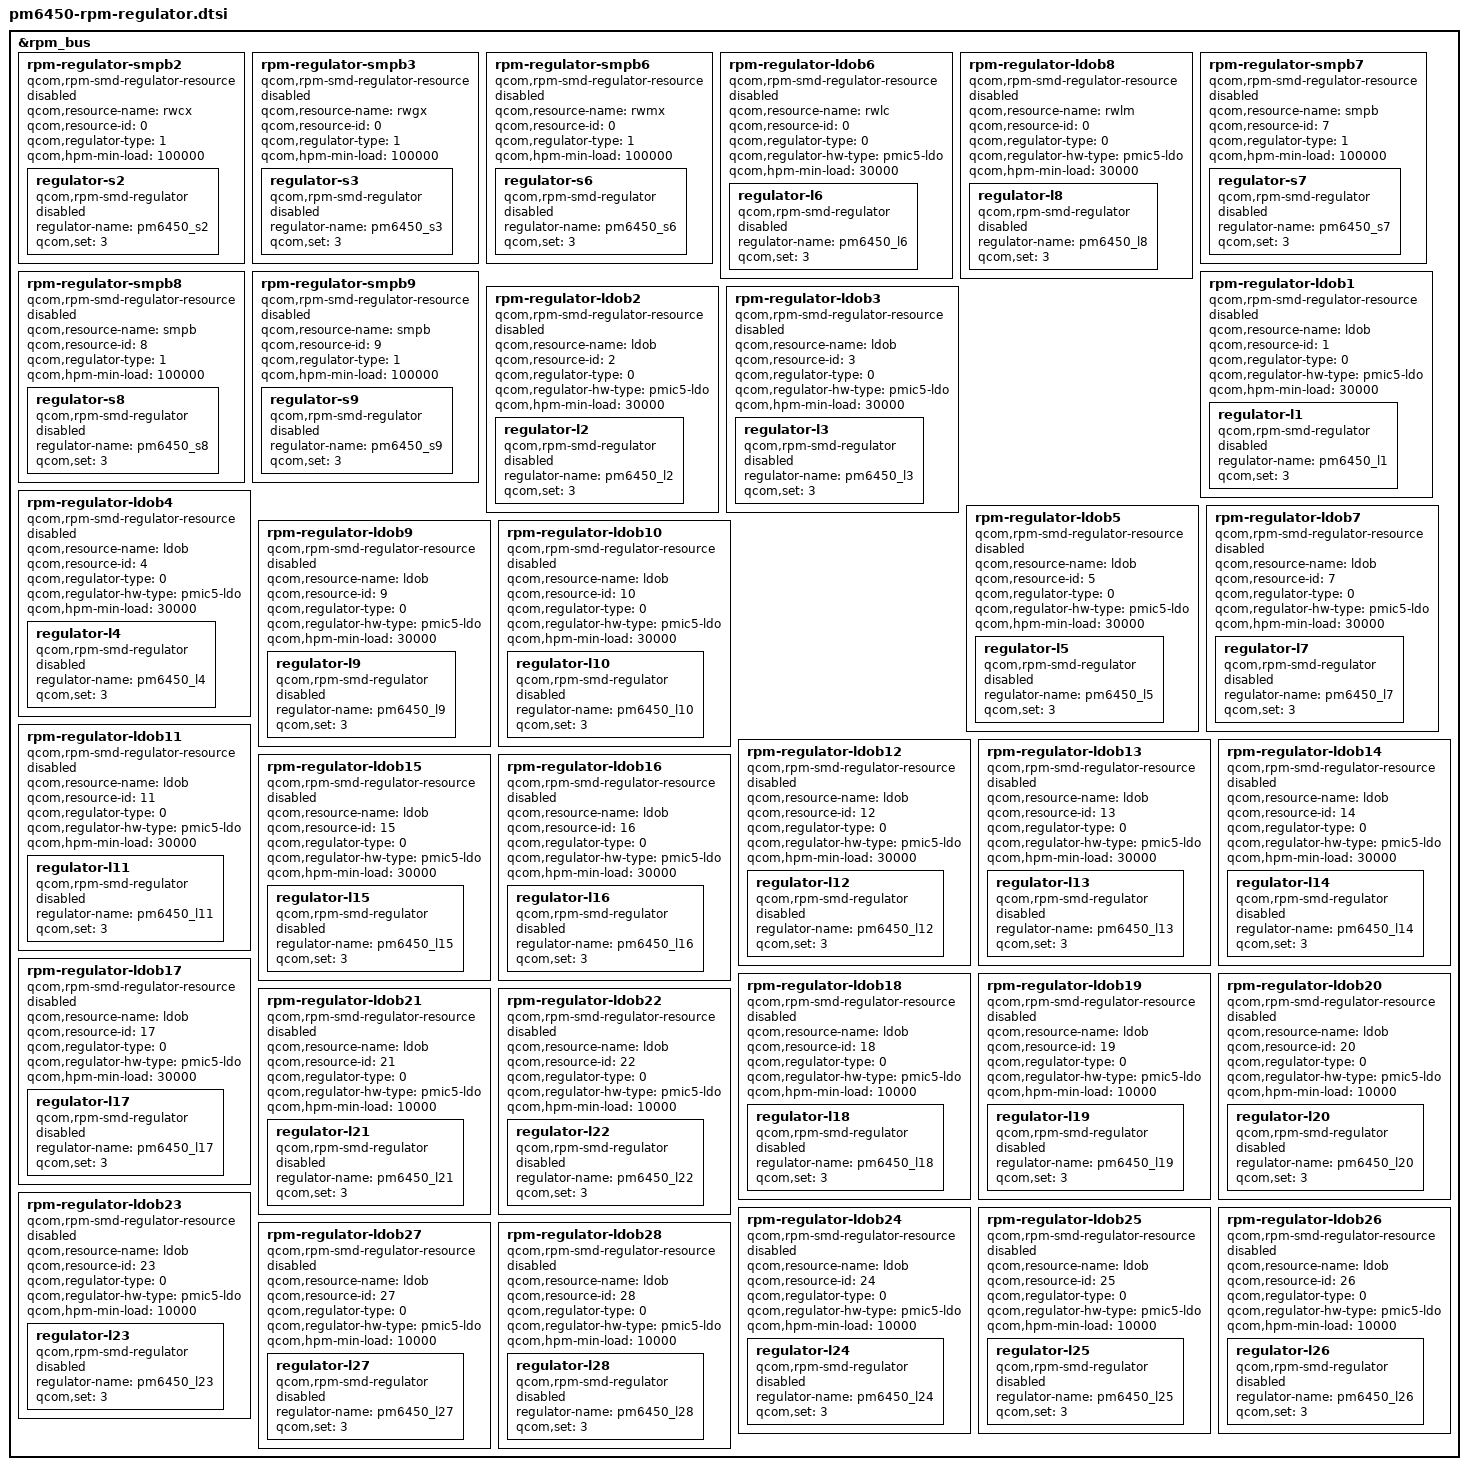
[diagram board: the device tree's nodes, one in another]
// SPDX-License-Identifier: BSD-3-Clause
/*
 * Copyright (c) Qualcomm Technologies, Inc. and/or its subsidiaries.
 */

&rpm_bus {
	/* VDD_CX */
	rpm-regulator-smpb2 {
		compatible = "qcom,rpm-smd-regulator-resource";
		qcom,resource-name = "rwcx";
		qcom,resource-id = <0>;
		qcom,regulator-type = <1>;
		qcom,hpm-min-load = <100000>;
		status = "disabled";

		regulator-s2 {
			compatible = "qcom,rpm-smd-regulator";
			regulator-name = "pm6450_s2";
			qcom,set = <3>;
			status = "disabled";
		};
	};

	/* VDD_GFX */
	rpm-regulator-smpb3 {
		compatible = "qcom,rpm-smd-regulator-resource";
		qcom,resource-name = "rwgx";
		qcom,resource-id = <0>;
		qcom,regulator-type = <1>;
		qcom,hpm-min-load = <100000>;
		status = "disabled";

		regulator-s3 {
			compatible = "qcom,rpm-smd-regulator";
			regulator-name = "pm6450_s3";
			qcom,set = <3>;
			status = "disabled";
		};
	};

	/* VDD_MX */
	rpm-regulator-smpb6 {
		compatible = "qcom,rpm-smd-regulator-resource";
		qcom,resource-name = "rwmx";
		qcom,resource-id = <0>;
		qcom,regulator-type = <1>;
		qcom,hpm-min-load = <100000>;
		status = "disabled";

		regulator-s6 {
			compatible = "qcom,rpm-smd-regulator";
			regulator-name = "pm6450_s6";
			qcom,set = <3>;
			status = "disabled";
		};
	};

	rpm-regulator-ldob6 {
		compatible = "qcom,rpm-smd-regulator-resource";
		qcom,resource-name = "rwlc";
		qcom,resource-id = <0>;
		qcom,regulator-type = <0>;
		qcom,regulator-hw-type = "pmic5-ldo";
		qcom,hpm-min-load = <30000>;
		status = "disabled";

		regulator-l6 {
			compatible = "qcom,rpm-smd-regulator";
			regulator-name = "pm6450_l6";
			qcom,set = <3>;
			status = "disabled";
		};
	};

	rpm-regulator-ldob8 {
		compatible = "qcom,rpm-smd-regulator-resource";
		qcom,resource-name = "rwlm";
		qcom,resource-id = <0>;
		qcom,regulator-type = <0>;
		qcom,regulator-hw-type = "pmic5-ldo";
		qcom,hpm-min-load = <30000>;
		status = "disabled";

		regulator-l8 {
			compatible = "qcom,rpm-smd-regulator";
			regulator-name = "pm6450_l8";
			qcom,set = <3>;
			status = "disabled";
		};
	};

	rpm-regulator-smpb7 {
		compatible = "qcom,rpm-smd-regulator-resource";
		qcom,resource-name = "smpb";
		qcom,resource-id = <7>;
		qcom,regulator-type = <1>;
		qcom,hpm-min-load = <100000>;
		status = "disabled";

		regulator-s7 {
			compatible = "qcom,rpm-smd-regulator";
			regulator-name = "pm6450_s7";
			qcom,set = <3>;
			status = "disabled";
		};
	};

	rpm-regulator-smpb8 {
		compatible = "qcom,rpm-smd-regulator-resource";
		qcom,resource-name = "smpb";
		qcom,resource-id = <8>;
		qcom,regulator-type = <1>;
		qcom,hpm-min-load = <100000>;
		status = "disabled";

		regulator-s8 {
			compatible = "qcom,rpm-smd-regulator";
			regulator-name = "pm6450_s8";
			qcom,set = <3>;
			status = "disabled";
		};
	};

	rpm-regulator-smpb9 {
		compatible = "qcom,rpm-smd-regulator-resource";
		qcom,resource-name = "smpb";
		qcom,resource-id = <9>;
		qcom,regulator-type = <1>;
		qcom,hpm-min-load = <100000>;
		status = "disabled";

		regulator-s9 {
			compatible = "qcom,rpm-smd-regulator";
			regulator-name = "pm6450_s9";
			qcom,set = <3>;
			status = "disabled";
		};
	};

	rpm-regulator-ldob1 {
		compatible = "qcom,rpm-smd-regulator-resource";
		qcom,resource-name = "ldob";
		qcom,resource-id = <1>;
		qcom,regulator-type = <0>;
		qcom,regulator-hw-type = "pmic5-ldo";
		qcom,hpm-min-load = <30000>;
		status = "disabled";

		regulator-l1 {
			compatible = "qcom,rpm-smd-regulator";
			regulator-name = "pm6450_l1";
			qcom,set = <3>;
			status = "disabled";
		};
	};

	rpm-regulator-ldob2 {
		compatible = "qcom,rpm-smd-regulator-resource";
		qcom,resource-name = "ldob";
		qcom,resource-id = <2>;
		qcom,regulator-type = <0>;
		qcom,regulator-hw-type = "pmic5-ldo";
		qcom,hpm-min-load = <30000>;
		status = "disabled";

		regulator-l2 {
			compatible = "qcom,rpm-smd-regulator";
			regulator-name = "pm6450_l2";
			qcom,set = <3>;
			status = "disabled";
		};
	};

	rpm-regulator-ldob3 {
		compatible = "qcom,rpm-smd-regulator-resource";
		qcom,resource-name = "ldob";
		qcom,resource-id = <3>;
		qcom,regulator-type = <0>;
		qcom,regulator-hw-type = "pmic5-ldo";
		qcom,hpm-min-load = <30000>;
		status = "disabled";

		regulator-l3 {
			compatible = "qcom,rpm-smd-regulator";
			regulator-name = "pm6450_l3";
			qcom,set = <3>;
			status = "disabled";
		};
	};

	rpm-regulator-ldob4 {
		compatible = "qcom,rpm-smd-regulator-resource";
		qcom,resource-name = "ldob";
		qcom,resource-id = <4>;
		qcom,regulator-type = <0>;
		qcom,regulator-hw-type = "pmic5-ldo";
		qcom,hpm-min-load = <30000>;
		status = "disabled";

		regulator-l4 {
			compatible = "qcom,rpm-smd-regulator";
			regulator-name = "pm6450_l4";
			qcom,set = <3>;
			status = "disabled";
		};
	};

	rpm-regulator-ldob5 {
		compatible = "qcom,rpm-smd-regulator-resource";
		qcom,resource-name = "ldob";
		qcom,resource-id = <5>;
		qcom,regulator-type = <0>;
		qcom,regulator-hw-type = "pmic5-ldo";
		qcom,hpm-min-load = <30000>;
		status = "disabled";

		regulator-l5 {
			compatible = "qcom,rpm-smd-regulator";
			regulator-name = "pm6450_l5";
			qcom,set = <3>;
			status = "disabled";
		};
	};

	rpm-regulator-ldob7 {
		compatible = "qcom,rpm-smd-regulator-resource";
		qcom,resource-name = "ldob";
		qcom,resource-id = <7>;
		qcom,regulator-type = <0>;
		qcom,regulator-hw-type = "pmic5-ldo";
		qcom,hpm-min-load = <30000>;
		status = "disabled";

		regulator-l7 {
			compatible = "qcom,rpm-smd-regulator";
			regulator-name = "pm6450_l7";
			qcom,set = <3>;
			status = "disabled";
		};
	};

	rpm-regulator-ldob9 {
		compatible = "qcom,rpm-smd-regulator-resource";
		qcom,resource-name = "ldob";
		qcom,resource-id = <9>;
		qcom,regulator-type = <0>;
		qcom,regulator-hw-type = "pmic5-ldo";
		qcom,hpm-min-load = <30000>;
		status = "disabled";

		regulator-l9 {
			compatible = "qcom,rpm-smd-regulator";
			regulator-name = "pm6450_l9";
			qcom,set = <3>;
			status = "disabled";
		};
	};

	rpm-regulator-ldob10 {
		compatible = "qcom,rpm-smd-regulator-resource";
		qcom,resource-name = "ldob";
		qcom,resource-id = <10>;
		qcom,regulator-type = <0>;
		qcom,regulator-hw-type = "pmic5-ldo";
		qcom,hpm-min-load = <30000>;
		status = "disabled";

		regulator-l10 {
			compatible = "qcom,rpm-smd-regulator";
			regulator-name = "pm6450_l10";
			qcom,set = <3>;
			status = "disabled";
		};
	};

	rpm-regulator-ldob11 {
		compatible = "qcom,rpm-smd-regulator-resource";
		qcom,resource-name = "ldob";
		qcom,resource-id = <11>;
		qcom,regulator-type = <0>;
		qcom,regulator-hw-type = "pmic5-ldo";
		qcom,hpm-min-load = <30000>;
		status = "disabled";

		regulator-l11 {
			compatible = "qcom,rpm-smd-regulator";
			regulator-name = "pm6450_l11";
			qcom,set = <3>;
			status = "disabled";
		};
	};

	rpm-regulator-ldob12 {
		compatible = "qcom,rpm-smd-regulator-resource";
		qcom,resource-name = "ldob";
		qcom,resource-id = <12>;
		qcom,regulator-type = <0>;
		qcom,regulator-hw-type = "pmic5-ldo";
		qcom,hpm-min-load = <30000>;
		status = "disabled";

		regulator-l12 {
			compatible = "qcom,rpm-smd-regulator";
			regulator-name = "pm6450_l12";
			qcom,set = <3>;
			status = "disabled";
		};
	};

	rpm-regulator-ldob13 {
		compatible = "qcom,rpm-smd-regulator-resource";
		qcom,resource-name = "ldob";
		qcom,resource-id = <13>;
		qcom,regulator-type = <0>;
		qcom,regulator-hw-type = "pmic5-ldo";
		qcom,hpm-min-load = <30000>;
		status = "disabled";

		regulator-l13 {
			compatible = "qcom,rpm-smd-regulator";
			regulator-name = "pm6450_l13";
			qcom,set = <3>;
			status = "disabled";
		};
	};

	rpm-regulator-ldob14 {
		compatible = "qcom,rpm-smd-regulator-resource";
		qcom,resource-name = "ldob";
		qcom,resource-id = <14>;
		qcom,regulator-type = <0>;
		qcom,regulator-hw-type = "pmic5-ldo";
		qcom,hpm-min-load = <30000>;
		status = "disabled";

		regulator-l14 {
			compatible = "qcom,rpm-smd-regulator";
			regulator-name = "pm6450_l14";
			qcom,set = <3>;
			status = "disabled";
		};
	};

	rpm-regulator-ldob15 {
		compatible = "qcom,rpm-smd-regulator-resource";
		qcom,resource-name = "ldob";
		qcom,resource-id = <15>;
		qcom,regulator-type = <0>;
		qcom,regulator-hw-type = "pmic5-ldo";
		qcom,hpm-min-load = <30000>;
		status = "disabled";

		regulator-l15 {
			compatible = "qcom,rpm-smd-regulator";
			regulator-name = "pm6450_l15";
			qcom,set = <3>;
			status = "disabled";
		};
	};

	rpm-regulator-ldob16 {
		compatible = "qcom,rpm-smd-regulator-resource";
		qcom,resource-name = "ldob";
		qcom,resource-id = <16>;
		qcom,regulator-type = <0>;
		qcom,regulator-hw-type = "pmic5-ldo";
		qcom,hpm-min-load = <30000>;
		status = "disabled";

		regulator-l16 {
			compatible = "qcom,rpm-smd-regulator";
			regulator-name = "pm6450_l16";
			qcom,set = <3>;
			status = "disabled";
		};
	};

	rpm-regulator-ldob17 {
		compatible = "qcom,rpm-smd-regulator-resource";
		qcom,resource-name = "ldob";
		qcom,resource-id = <17>;
		qcom,regulator-type = <0>;
		qcom,regulator-hw-type = "pmic5-ldo";
		qcom,hpm-min-load = <30000>;
		status = "disabled";

		regulator-l17 {
			compatible = "qcom,rpm-smd-regulator";
			regulator-name = "pm6450_l17";
			qcom,set = <3>;
			status = "disabled";
		};
	};

	rpm-regulator-ldob18 {
		compatible = "qcom,rpm-smd-regulator-resource";
		qcom,resource-name = "ldob";
		qcom,resource-id = <18>;
		qcom,regulator-type = <0>;
		qcom,regulator-hw-type = "pmic5-ldo";
		qcom,hpm-min-load = <10000>;
		status = "disabled";

		regulator-l18 {
			compatible = "qcom,rpm-smd-regulator";
			regulator-name = "pm6450_l18";
			qcom,set = <3>;
			status = "disabled";
		};
	};

	rpm-regulator-ldob19 {
		compatible = "qcom,rpm-smd-regulator-resource";
		qcom,resource-name = "ldob";
		qcom,resource-id = <19>;
		qcom,regulator-type = <0>;
		qcom,regulator-hw-type = "pmic5-ldo";
		qcom,hpm-min-load = <10000>;
		status = "disabled";

		regulator-l19 {
			compatible = "qcom,rpm-smd-regulator";
			regulator-name = "pm6450_l19";
			qcom,set = <3>;
			status = "disabled";
		};
	};

	rpm-regulator-ldob20 {
		compatible = "qcom,rpm-smd-regulator-resource";
		qcom,resource-name = "ldob";
		qcom,resource-id = <20>;
		qcom,regulator-type = <0>;
		qcom,regulator-hw-type = "pmic5-ldo";
		qcom,hpm-min-load = <10000>;
		status = "disabled";

		regulator-l20 {
			compatible = "qcom,rpm-smd-regulator";
			regulator-name = "pm6450_l20";
			qcom,set = <3>;
			status = "disabled";
		};
	};

	rpm-regulator-ldob21 {
		compatible = "qcom,rpm-smd-regulator-resource";
		qcom,resource-name = "ldob";
		qcom,resource-id = <21>;
		qcom,regulator-type = <0>;
		qcom,regulator-hw-type = "pmic5-ldo";
		qcom,hpm-min-load = <10000>;
		status = "disabled";

		regulator-l21 {
			compatible = "qcom,rpm-smd-regulator";
			regulator-name = "pm6450_l21";
			qcom,set = <3>;
			status = "disabled";
		};
	};

	rpm-regulator-ldob22 {
		compatible = "qcom,rpm-smd-regulator-resource";
		qcom,resource-name = "ldob";
		qcom,resource-id = <22>;
		qcom,regulator-type = <0>;
		qcom,regulator-hw-type = "pmic5-ldo";
		qcom,hpm-min-load = <10000>;
		status = "disabled";

		regulator-l22 {
			compatible = "qcom,rpm-smd-regulator";
			regulator-name = "pm6450_l22";
			qcom,set = <3>;
			status = "disabled";
		};
	};

	rpm-regulator-ldob23 {
		compatible = "qcom,rpm-smd-regulator-resource";
		qcom,resource-name = "ldob";
		qcom,resource-id = <23>;
		qcom,regulator-type = <0>;
		qcom,regulator-hw-type = "pmic5-ldo";
		qcom,hpm-min-load = <10000>;
		status = "disabled";

		regulator-l23 {
			compatible = "qcom,rpm-smd-regulator";
			regulator-name = "pm6450_l23";
			qcom,set = <3>;
			status = "disabled";
		};
	};

	rpm-regulator-ldob24 {
		compatible = "qcom,rpm-smd-regulator-resource";
		qcom,resource-name = "ldob";
		qcom,resource-id = <24>;
		qcom,regulator-type = <0>;
		qcom,regulator-hw-type = "pmic5-ldo";
		qcom,hpm-min-load = <10000>;
		status = "disabled";

		regulator-l24 {
			compatible = "qcom,rpm-smd-regulator";
			regulator-name = "pm6450_l24";
			qcom,set = <3>;
			status = "disabled";
		};
	};

	rpm-regulator-ldob25 {
		compatible = "qcom,rpm-smd-regulator-resource";
		qcom,resource-name = "ldob";
		qcom,resource-id = <25>;
		qcom,regulator-type = <0>;
		qcom,regulator-hw-type = "pmic5-ldo";
		qcom,hpm-min-load = <10000>;
		status = "disabled";

		regulator-l25 {
			compatible = "qcom,rpm-smd-regulator";
			regulator-name = "pm6450_l25";
			qcom,set = <3>;
			status = "disabled";
		};
	};

	rpm-regulator-ldob26 {
		compatible = "qcom,rpm-smd-regulator-resource";
		qcom,resource-name = "ldob";
		qcom,resource-id = <26>;
		qcom,regulator-type = <0>;
		qcom,regulator-hw-type = "pmic5-ldo";
		qcom,hpm-min-load = <10000>;
		status = "disabled";

		regulator-l26 {
			compatible = "qcom,rpm-smd-regulator";
			regulator-name = "pm6450_l26";
			qcom,set = <3>;
			status = "disabled";
		};
	};

	rpm-regulator-ldob27 {
		compatible = "qcom,rpm-smd-regulator-resource";
		qcom,resource-name = "ldob";
		qcom,resource-id = <27>;
		qcom,regulator-type = <0>;
		qcom,regulator-hw-type = "pmic5-ldo";
		qcom,hpm-min-load = <10000>;
		status = "disabled";

		regulator-l27 {
			compatible = "qcom,rpm-smd-regulator";
			regulator-name = "pm6450_l27";
			qcom,set = <3>;
			status = "disabled";
		};
	};

	rpm-regulator-ldob28 {
		compatible = "qcom,rpm-smd-regulator-resource";
		qcom,resource-name = "ldob";
		qcom,resource-id = <28>;
		qcom,regulator-type = <0>;
		qcom,regulator-hw-type = "pmic5-ldo";
		qcom,hpm-min-load = <10000>;
		status = "disabled";

		regulator-l28 {
			compatible = "qcom,rpm-smd-regulator";
			regulator-name = "pm6450_l28";
			qcom,set = <3>;
			status = "disabled";
		};
	};
};
